# TC37XPD register map
Vendor: Infineon; Series: ATVMC; File version: 100
CPU: other r0p0, little endian, MPU, FPU, vendor SysTick, 4 interrupt priority bits
Registers are 32-bit, read-write, reset 0x0 unless marked. A register's access mark holds for its fields unless they carry their own. Offsets are from the block's base; [hi:lo] are bit positions; lines under a group give offsets from that group; {n}, {i} and the like mark numbered series.

## SBCU — FPI Bus Control Unit
Base 0xF0030000
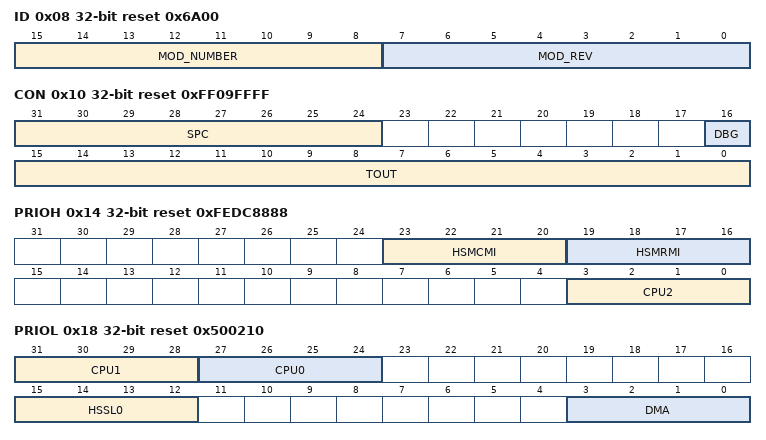
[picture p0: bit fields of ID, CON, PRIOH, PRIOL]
0x08 ID ro reset 0x6A00 (reset mask 0xFFFFFF00) — Module Identification Register resetvalue={Application Reset:0x6A00}
  [15:8] MOD_NUMBER — Module Number Value MOD NUMBER. This bit field defines a module identification number. The value for the LBCU module is 006AH.
  [7:0] MOD_REV — Module Revision Number MOD REV. This bit field defines the module revision number. The value of a module revision starts with 01H first revision .
0x10 CON reset 0xFF09FFFF — BCU Control Register resetvalue={Application Reset:0x0FF09FFFF}
  [31:24] SPC — Starvation Period Control. Determines the sample period for the starvation counter. Must be larger than the number of masters. The reset value is FF H .
  [16] DBG — BCU Debug Trace Enable. The bit enables disables the error capture mechanism for the registers BCU ECON BCU EADD BCU EDAT. The bit does not affect the SMU alarm or the BCU interrupt that are send on detection case of an error condition.
  [15:0] TOUT — BCU Bus Time Out Value. The bit field determines the number of System Peripheral Bus time out cycles. Default after reset is FFFF H 65536 bus cycles . TOUT value must be gt 5.
0x14 PRIOH reset 0xFEDC8888 — Arbiter Priority Register High resetvalue={Application Reset:0x0FEDCBA98,Application Reset:0x0FEDC8888,Application Reset:0x0FEDCBA98}
  [23:20] HSMCMI — HSMCMI Priority Index 13 . This bit field defines the priority on the SPB for HSMCMI access to the SPB.
  [19:16] HSMRMI — HSMRMI Priority Index 12 . This bit field defines the priority on the SPB for HSMRMI access to the SPB.
  [3:0] CPU2 — CPU2 Priority Index 8 . This bit field defines the priority on the SPB for CPU2 access to the SPB.
0x18 PRIOL reset 0x500210 (reset mask 0x1F34FFF) — Arbiter Priority Register Low resetvalue={Application Reset:0x76543210,Application Reset:0x088543210,Application Reset:0x76588210}
  [31:28] CPU1 — CPU1 Priority Index 7 . This bit field defines the priority on the SPB for CPU1 access to the SPB. This bit field contains the master priority for master connected to BCU request input 7.
  [27:24] CPU0 — CPU0 Priority Index 6 . This bit field defines the priority on the SPB for CPU0 access to the SPB. Position 180 6 180 of the Req Lock Grant BCU input vector set is used in the EDC implementation for Req Lock error injection. Therefore this position shall be used for a CPU.
  [15:12] HSSL0 — HSSL0 Priority Index 3 . This bit field defines the priority on the SPB for HSSL0 access to the SPB.
  [3:0] DMA — DMA Cerberus Priority Index 0 . This bit field defines the priority on the SPB for DMA and Cerberus access to the SPB.
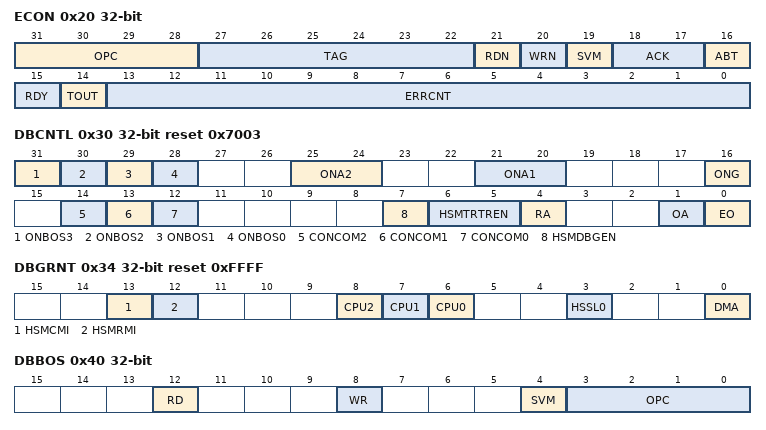
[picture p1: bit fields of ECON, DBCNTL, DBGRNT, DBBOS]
0x20 ECON — BCU Error Control Capture Register resetvalue={Application Reset:0x0}
  [31:28] OPC — FPI Bus Operation Code Signals. The FPI 160 Bus operation codes are defined in CROSSREFERENCE .
  [27:22] TAG — FPI Bus Master Tag Number Signals. This bit field indicates the FPI 160 Bus master TAG number definitions see CROSSREFERENCE .
  [21] RDN — State of FPI Bus Read Signal. This bit indicates whether the FPI 160 Bus error occurred at a read cycle see CROSSREFERENCE .
  [20] WRN — State of FPI Bus Write Signal. This bit indicates whether the FPI 160 Bus error occurred at a write cycle see CROSSREFERENCE .
  [19] SVM — State of FPI Bus Supervisor Mode Signal. This bit indicates whether the FPI 160 Bus error occurred in Supervisor Mode or in User Mode.
  [18:17] ACK — State of FPI Bus Acknowledge Signals. This bit field indicates the acknowledge code that has been output by the selected slave at an FPI 160 Bus error. Coding see CROSSREFERENCE .
  [16] ABT — State of FPI Bus Abort Signal. This bit indicates the state of the abort signal at an FBI 160 Bus error.
  [15] RDY — State of FPI Bus Ready Signal. This bit indicates the state of the ready signal at an FBI 160 Bus error.
  [14] TOUT — State of FPI Bus Time Out Signal. This bit indicates the state of the time out signal at an FBI 160 Bus error.
  [13:0] ERRCNT — FPI Bus Error Counter. ERRCNT is incremented on every occurrence of an FPI 160 Bus error. ERRCNT is reset to 0 after the ECON register is read. Aborted accesses to a 0 wait state SPB slave may also increment ERRCNT when the slave generates an error acknowledge.
0x24 EADD — BCU Error Address Capture Register resetvalue={Application Reset:0x0}
  [31:0] FPIADR — Captured FPI Bus Address FPIADR. This bit field holds the 32 bit FPI Bus address that has been captured at an FPI Bus error. Note that if multiple bus errors occurred only the address of the first bus error is captured.
0x28 EDAT — BCU Error Data Capture Register resetvalue={Application Reset:0x0}
  [31:0] FPIDAT — Captured FPI Bus Data FPIDAT. This bit field holds the 32 bit FPI Bus data that has been captured at an FPI Bus error. Note that if multiple bus errors occurred only the data of the first bus error is captured. No data are captured from transactions generated by the SHE module.
0x30 DBCNTL access per field reset 0x7003 — BCU Debug Control Register resetvalue={Debug Reset:0x7003}
  [31] ONBOS3 rw — Read Signal Trigger Condition
  [30] ONBOS2 rw — Write Signal Trigger Condition
  [29] ONBOS1 rw — Supervisor Mode Signal Trigger Condition
  [28] ONBOS0 rw — Op code Signal Status Trigger Condition
  [25:24] ONA2 rw — Address 2 Trigger Control. See also CROSSREFERENCE .
  [21:20] ONA1 rw — Address 1 Trigger Control. See also CROSSREFERENCE .
  [16] ONG rw — Grant Trigger Enable
  [14] CONCOM2 rw — Address and Signal Trigger Relation
  [13] CONCOM1 rw — Address 1 and Address 2 Trigger Relation
  [12] CONCOM0 rw — Grant and Address Trigger Relation
  [7] HSMDBGEN ro — Status of HSM Debug Mode
  [6:5] HSMTRTREN ro — Status of HSM Transaction Trace Logic
  [4] RA wo — Rearm BCU Breakpoint Logic. Writing a 1 to this bit rearms BCU breakpoint logic and sets bit OA 160 160 1. RA is always reads as 0.
  [1] OA ro — Status of BCU Breakpoint Logic. The OA bit is set by writing a 1 to bit RA. When OA is set registers DBGNTT DBADRT and DBDAT are reset. Also DBBOST is reset with the exception of the bit field FPIRST.
  [0] EO ro — Status of BCU Debug Support Enable. This bit is controlled by the Cerberus and enables the BCU debug support.
0x34 DBGRNT reset 0xFFFF — SBCU Debug Grant Mask Register resetvalue={Debug Reset:0x0FFFF}
  [13] HSMCMI — HSM Cache Master Interface Grant Trigger Enable
  [12] HSMRMI — HSM Register Master Interface Grant Trigger Enable
  [8] CPU2 — CPU2 Grant Trigger Enable
  [7] CPU1 — CPU1 Grant Trigger Enable
  [6] CPU0 — CPU0 Grant Trigger Enable
  [3] HSSL0 — HSSL0 Trigger Enable
  [0] DMA — DMA Cerberus Trigger Enable. TC39xA DMAH
0x38 DBADR1 — BCU Debug Address 1 Register resetvalue={Debug Reset:0x0}
  [31:0] ADR1 — Debug Trigger Address 1. This register contains the address for the address 1 trigger event generation.
0x3C DBADR2 — BCU Debug Address 2 Register resetvalue={Debug Reset:0x0}
  [31:0] ADR2 — Debug Trigger Address 2. This register contains the address for the address 2 trigger event generation.
0x40 DBBOS — BCU Debug Bus Operation Signals Register resetvalue={Debug Reset:0x0}
  [12] RD — Write Signal for Status Debug Trigger. This bit determines the state of the RD signal of an FPI 160 Bus transaction for which a signal status debug trigger event is generated if enabled by DBCNTL.ONBOS3 160 160 1 .
  [8] WR — Write Signal for Status Debug Trigger. This bit determines the state of the WR signal of an FPI 160 Bus transaction for which a signal status debug trigger event is generated if enabled by DBCNTL.ONBOS2 160 160 1 .
  [4] SVM — SVM Signal for Status Debug Trigger. This bit determines the mode of an FPI 160 Bus transaction for which a signal status debug trigger event is generated if enabled by DBCNTL.ONBOS1 160 160 1 .
  [3:0] OPC — Opcode for Signal Status Debug Trigger. This bit field determines the type opcode of an FPI 160 Bus transaction for which a signal status debug trigger event is generated if enabled by DBCNTL.ONBOS0 160 160 1 . Other bit combinations are reserved.
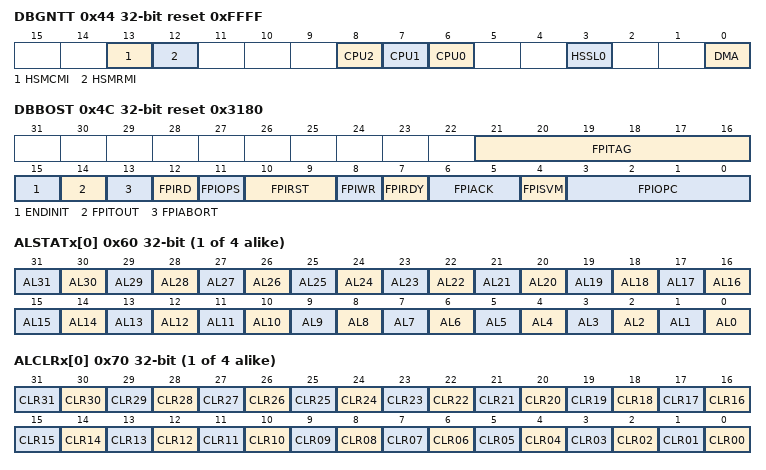
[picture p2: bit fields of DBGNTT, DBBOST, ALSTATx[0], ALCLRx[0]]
0x44 DBGNTT ro reset 0xFFFF — SBCU Debug Trapped Master Register resetvalue={Debug Reset:0x0FFFF}
  [13] HSMCMI — HSM Cache FPI Bus Master Interface Status. This bit indicates whether the HSM was FPI 160 Bus master when the break trigger event occurred.
  [12] HSMRMI — HSM Register FPI Bus Master Interface Status. This bit indicates whether the HSM was FPI 160 Bus master when the break trigger event occurred.
  [8] CPU2 — CPU2 Grant Trigger Enable
  [7] CPU1 — CPU1 FPI Bus Master Status. This bit indicates whether the CPU1 was FPI 160 Bus master when the break trigger event occurred.
  [6] CPU0 — CPU0 FPI Bus Master Status. This bit indicates whether the CPU0 was FPI 160 Bus master when the break trigger event occurred. Position 180 6 180 of the Req Lock Grant BCU input vector set is used in the EDC implementation for Req Lock error injection. Therefore this position shall be used on the SPB for CPU on BBB for the Bridge SRI2BBB .
  [3] HSSL0 — HSSL 0 FPI Bus Master Status. This bit indicates whether the HSSL 0 was FPI 160 Bus master when the break trigger event occurred.
  [0] DMA — DMA Cerberus FPI Bus Master Status. This bit indicates whether the DMA or Cerberus was FPI 160 Bus master when the break trigger event occurred.
0x48 DBADRT ro — BCU Debug Trapped Address Register resetvalue={Debug Reset:0x0}
  [31:0] FPIADR — FPI Bus Address Status. This register contains the FPI 160 Bus address that was captured when the OCDS break trigger event occurred.
0x4C DBBOST ro reset 0x3180 — BCU Debug Trapped Bus Operation Signals Register resetvalue={Debug Reset:0x3180}
  [21:16] FPITAG — FPI Bus Master TAG Status. This bit field indicates the master TAG captured from the FPI 160 Bus signal lines when the BCU break trigger event occurred see CROSSREFERENCE . The master TAG identifies the master of the transfer which generated BCU break trigger event.
  [15] ENDINIT — FPI Bus Endinit Status. This bit indicates the ENDINIT signal status captured from the FPI 160 Bus signal lines when the BCU break trigger event occurred.
  [14] FPITOUT — FPI Bus Time out Status. This bit indicates the time out signal status captured from the FPI 160 Bus signal lines when the BCU break trigger event occurred.
  [13] FPIABORT — FPI Bus Abort Status. This bit indicates the abort signal status captured from the FPI 160 Bus signal lines when the BCU break trigger event occurred.
  [12] FPIRD — FPI Bus Read Indication Status. This bit indicates the read signal status captured from the FPI 160 Bus signal lines when the BCU break trigger event occurred.
  [11] FPIOPS — FPI Bus OCDS Suspend Status. This bit indicates the OCDS suspend signal status captured from the FPI 160 Bus signal lines when the BCU break trigger event occurred.
  [10:9] FPIRST — FPI Bus Reset Status. This bit field indicates the reset signal status captured from the FPI 160 Bus signal lines when the BCU break trigger event occurred. Others 160 160 160 160 160 Reserved
  [8] FPIWR — FPI Bus Write Indication Status. This bit indicates the write signal status captured from the FPI 160 Bus signal lines when the BCU break trigger event occurred.
  [7] FPIRDY — FPI Bus Ready Status. This bit indicates the ready signal status captured from the FPI 160 Bus signal lines when the BCU break trigger event occurred.
  [6:5] FPIACK — FPI Bus Acknowledge Status. This bit field indicates the acknowledge signal status captured from the FPI 160 Bus signal lines when the BCU break trigger event occurred. Coding see CROSSREFERENCE .
  [4] FPISVM — FPI Bus Supervisor Mode Status. This bit indicates the state of the Supervisor Mode signal captured from the FPI 160 Bus signal lines when the BCU break trigger event occurred.
  [3:0] FPIOPC — FPI Bus Opcode Status. This bit field indicates the type opcode of the FPI 160 Bus transaction captured from the FPI 160 Bus signal lines when the BCU break trigger event occurred. Other bit combinations are reserved.
0x50 DBDAT ro — BCU Debug Data Status Register resetvalue={Debug Reset:0x0}
  [31:0] FPIDATA — FPI Bus Data Status. This register contains the FPI 160 Bus data that was captured when the OCDS break trigger event occurred.
{0x60+4i} ALSTATx[{i}] (i=0..3) ro — BCU EDC Alarm Status Register 0 resetvalue={Debug Reset:0x0}
  [n] AL{n} (n=0..31) — Alarm 31. The Alarm bit shows if an EDC error was detected in an active phase of the related FPI Slave Master interface.
{0x70+4i} ALCLRx[{i}] (i=0..3) wo — BCU EDC Alarm Clear Register 0 resetvalue={Debug Reset:0x0}
  [n] CLR{n:02} (n=0..31) — Clear alarm 31. The Alarm bit shows if an EDC error was detected in an active phase of the related FPI Slave Master interface.
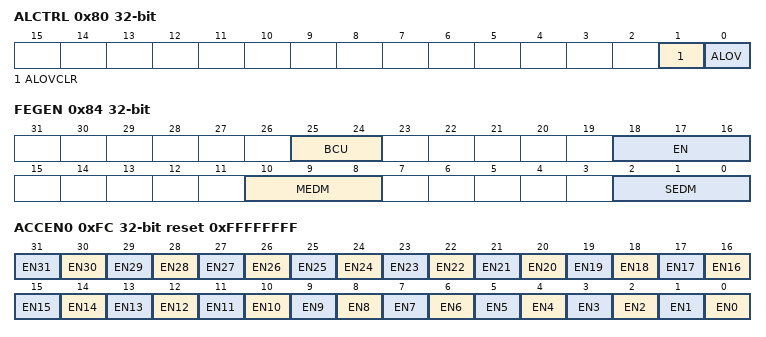
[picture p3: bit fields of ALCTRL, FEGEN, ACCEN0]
0x80 ALCTRL access per field — BCU EDC Alarm Control Register resetvalue={Debug Reset:0x0}
  [1] ALOVCLR wo — Alarm Overflow Clear. The ALOVCLR bit is required to reset the ALOV bit.
  [0] ALOV ro — Alarm Overflow. The ALOV bit is set if multiple FPI EDC alarms for the same FPI slave or the same FPI master were detected while the related ALSTATx y bit was still set. Some errors result in a static fault situation for example address phase data phase or data enable signal faults. Static faults do not generate multiple alarms and will will not set the ALOV bit.
0x84 FEGEN — FPI Error Generation Control Register resetvalue={Debug Reset:0x0}
  [25:24] BCU — BCU Type of Error. Other bit combinations are reserved and do not inject errors.
  [18:16] EN — Enable Signal Type of Error. The enable signals errors are injected by inverting the signal. For each group of enable signals that is checked gt 1 signal active error the enable signal related to BCU CPU0 is inverted. Other bit combinations are reserved and do not inject errors.
  [10:8] MEDM — MEDM Master Encoder Type of Error. The errors are injected in the FPI EDC encoders related to CPU0 SPB . Other bit combinations are reserved and do not inject errors.
  [2:0] SEDM — SEDM Slave Encoder . The errors are injected in the FPI EDC encoders related to the BCU SPB . Other bit combinations are reserved and do not inject errors.
0xFC ACCEN0 reset 0xFFFFFFFF — Access Enable Register 0 resetvalue={Application Reset:0x0FFFFFFFF}
  [n] EN{n} (n=0..31) — Access Enable for Master TAG ID 31. This bit enables write access to the module kernel addresses for transactions with the Master TAG ID n
